# STM32F105 register map
File version: 1.3
CPU: CM3 r1p1, little endian, no MPU, no FPU, 4 interrupt priority bits
Registers are 32-bit, read-write, reset 0x0 unless marked. A register's access mark holds for its fields unless they carry their own. Offsets are from the block's base; [hi:lo] are bit positions; {n}, {i} and the like mark numbered series; 'fields as' and 'values as' point back to an identical list.

## UART4 — Universal asynchronous receiver transmitter
Base 0x40004C00
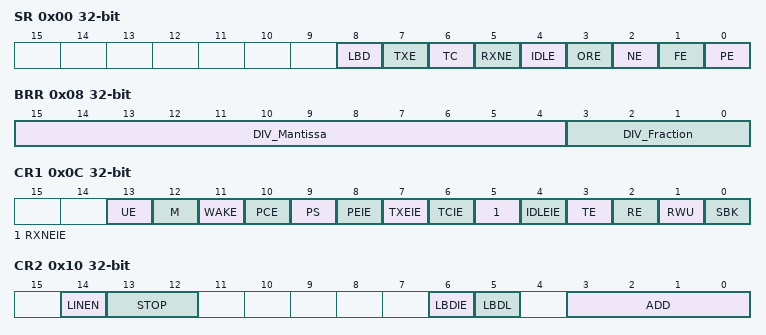
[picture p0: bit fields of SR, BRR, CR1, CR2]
0x00 SR access per field — UART4 SR
  [8] LBD rw — LIN break detection flag
  [7] TXE ro — Transmit data register empty
  [6] TC rw — Transmission complete
  [5] RXNE rw — Read data register not empty
  [4] IDLE ro — IDLE line detected
  [3] ORE ro — Overrun error
  [2] NE ro — Noise error flag
  [1] FE ro — Framing error
  [0] PE ro — Parity error
0x04 DR — UART4 DR
  [8:0] DR
0x08 BRR — UART4 BRR
  [15:4] DIV_Mantissa, [3:0] DIV_Fraction
0x0C CR1 — UART4 CR1
  [13] UE — USART enable
  [12] M — Word length
  [11] WAKE — Wakeup method
  [10] PCE — Parity control enable
  [9] PS — Parity selection
  [8] PEIE — PE interrupt enable
  [7] TXEIE — TXE interrupt enable
  [6] TCIE — Transmission complete interrupt enable
  [5] RXNEIE — RXNE interrupt enable
  [4] IDLEIE — IDLE interrupt enable
  [3] TE — Transmitter enable
  [2] RE — Receiver enable
  [1] RWU — Receiver wakeup
  [0] SBK — Send break
0x10 CR2 — UART4 CR2
  [14] LINEN — LIN mode enable
  [13:12] STOP — STOP bits
  [6] LBDIE — LIN break detection interrupt enable
  [5] LBDL — lin break detection length
  [3:0] ADD — Address of the USART node
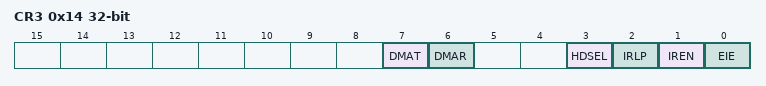
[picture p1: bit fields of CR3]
0x14 CR3 — UART4 CR3
  [7] DMAT — DMA enable transmitter
  [6] DMAR — DMA enable receiver
  [3] HDSEL — Half-duplex selection
  [2] IRLP — IrDA low-power
  [1] IREN — IrDA mode enable
  [0] EIE — Error interrupt enable

## UART5 — Universal asynchronous receiver transmitter
Base 0x40005000
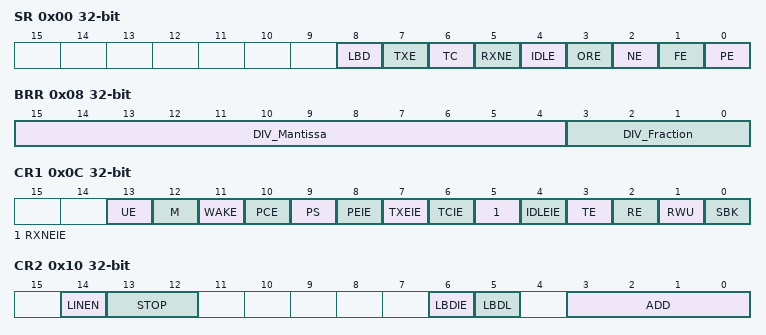
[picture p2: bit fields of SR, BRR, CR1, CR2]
0x00 SR access per field — UART5 SR
  [8] LBD rw, [7] TXE ro, [6] TC rw, [5] RXNE rw, [4] IDLE ro, [3] ORE ro, [2] NE ro, [1] FE ro, [0] PE ro
0x04 DR — UART5 DR
  [8:0] DR
0x08 BRR — UART5 BRR
  [15:4] DIV_Mantissa, [3:0] DIV_Fraction
0x0C CR1 — UART5 CR1
  [13] UE, [12] M, [11] WAKE, [10] PCE, [9] PS, [8] PEIE, [7] TXEIE, [6] TCIE, [5] RXNEIE, [4] IDLEIE, [3] TE, [2] RE, [1] RWU, [0] SBK
0x10 CR2 — UART5 CR2
  [14] LINEN, [13:12] STOP, [6] LBDIE, [5] LBDL, [3:0] ADD
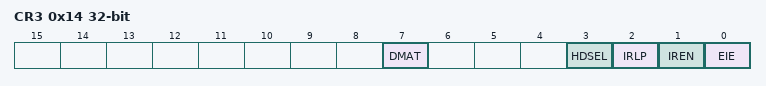
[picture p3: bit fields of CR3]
0x14 CR3 — UART5 CR3
  [7] DMAT — DMA enable transmitter
  [3] HDSEL — Half-duplex selection
  [2] IRLP — IrDA low-power
  [1] IREN — IrDA mode enable
  [0] EIE — Error interrupt enable

## USB_OTG_HOST — USB on the go full speed
Base 0x50000400
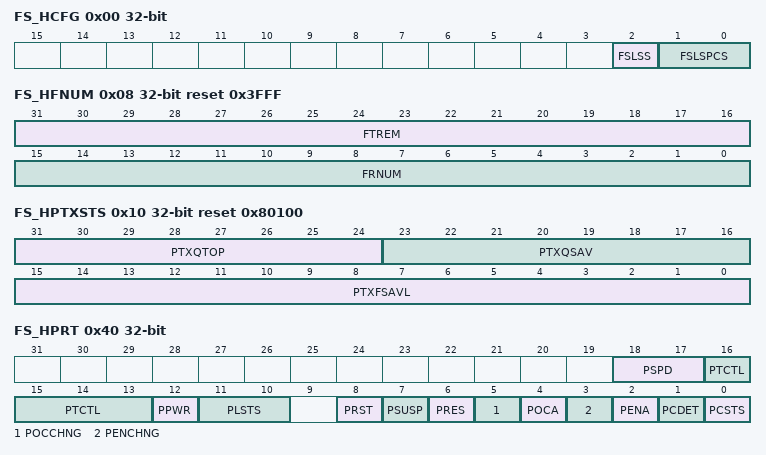
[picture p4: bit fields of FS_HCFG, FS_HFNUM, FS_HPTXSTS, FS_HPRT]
0x00 FS_HCFG access per field — OTG_FS host configuration register (OTG_FS_HCFG)
  [2] FSLSS ro — FS- and LS-only support
  [1:0] FSLSPCS rw — FS/LS PHY clock select
0x04 HFIR reset 0xEA60 — OTG_FS Host frame interval register
  [15:0] FRIVL — Frame interval
0x08 FS_HFNUM ro reset 0x3FFF — OTG_FS host frame number/frame time remaining register (OTG_FS_HFNUM)
  [31:16] FTREM — Frame time remaining
  [15:0] FRNUM — Frame number
0x10 FS_HPTXSTS access per field reset 0x80100 — OTG_FS_Host periodic transmit FIFO/queue status register (OTG_FS_HPTXSTS)
  [31:24] PTXQTOP ro — Top of the periodic transmit request queue
  [23:16] PTXQSAV ro — Periodic transmit request queue space available
  [15:0] PTXFSAVL rw — Periodic transmit data FIFO space available
0x14 HAINT ro — OTG_FS Host all channels interrupt register
  [15:0] HAINT — Channel interrupts
0x18 HAINTMSK — OTG_FS host all channels interrupt mask register
  [15:0] HAINTM — Channel interrupt mask
0x40 FS_HPRT access per field — OTG_FS host port control and status register (OTG_FS_HPRT)
  [18:17] PSPD ro — Port speed
  [16:13] PTCTL rw — Port test control
  [12] PPWR rw — Port power
  [11:10] PLSTS ro — Port line status
  [8] PRST rw — Port reset
  [7] PSUSP rw — Port suspend
  [6] PRES rw — Port resume
  [5] POCCHNG rw — Port overcurrent change
  [4] POCA ro — Port overcurrent active
  [3] PENCHNG rw — Port enable/disable change
  [2] PENA rw — Port enable
  [1] PCDET rw — Port connect detected
  [0] PCSTS ro — Port connect status
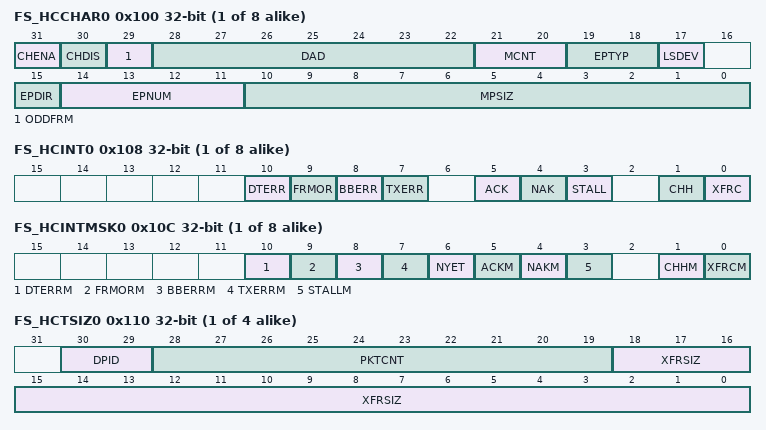
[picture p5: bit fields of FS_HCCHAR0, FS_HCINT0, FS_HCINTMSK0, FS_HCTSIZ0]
{0x100+0x20*i} FS_HCCHAR{i} (i=0..7) — OTG_FS host channel-{i} characteristics register (OTG_FS_HCCHAR{i})
  [31] CHENA — Channel enable
  [30] CHDIS — Channel disable
  [29] ODDFRM — Odd frame
  [28:22] DAD — Device address
  [21:20] MCNT — Multicount
  [19:18] EPTYP — Endpoint type
  [17] LSDEV — Low-speed device
  [15] EPDIR — Endpoint direction
  [14:11] EPNUM — Endpoint number
  [10:0] MPSIZ — Maximum packet size
{0x108+0x20*i} FS_HCINT{i} (i=0..7) — OTG_FS host channel-{i} interrupt register (OTG_FS_HCINT{i})
  [10] DTERR — Data toggle error
  [9] FRMOR — Frame overrun
  [8] BBERR — Babble error
  [7] TXERR — Transaction error
  [5] ACK — ACK response received/transmitted interrupt
  [4] NAK — NAK response received interrupt
  [3] STALL — STALL response received interrupt
  [1] CHH — Channel halted
  [0] XFRC — Transfer completed
{0x10C+0x20*i} FS_HCINTMSK{i} (i=0..7) — OTG_FS host channel-{i} mask register (OTG_FS_HCINTMSK{i})
  [10] DTERRM — Data toggle error mask
  [9] FRMORM — Frame overrun mask
  [8] BBERRM — Babble error mask
  [7] TXERRM — Transaction error mask
  [6] NYET — response received interrupt mask
  [5] ACKM — ACK response received/transmitted interrupt mask
  [4] NAKM — NAK response received interrupt mask
  [3] STALLM — STALL response received interrupt mask
  [1] CHHM — Channel halted mask
  [0] XFRCM — Transfer completed mask
{0x110+0x20*i} FS_HCTSIZ{i} (i=0..3) — OTG_FS host channel-{i} transfer size register
  [30:29] DPID — Data PID
  [28:19] PKTCNT — Packet count
  [18:0] XFRSIZ — Transfer size
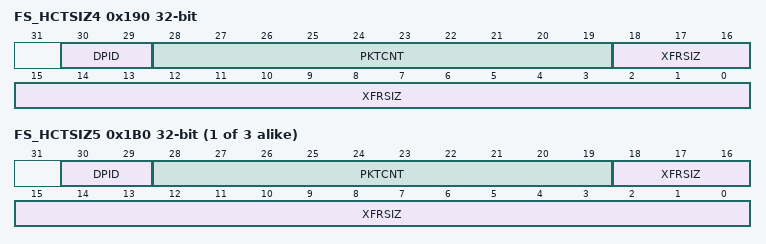
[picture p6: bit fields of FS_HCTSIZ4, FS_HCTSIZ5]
0x190 FS_HCTSIZ4 — OTG_FS host channel-x transfer size register
  fields as FS_HCTSIZ0
{0x110+0x20*i} FS_HCTSIZ{i} (i=5..7) — OTG_FS host channel-{i} transfer size register
  fields as FS_HCTSIZ0

## USB_OTG_PWRCLK — USB on the go full speed
Base 0x50000E00
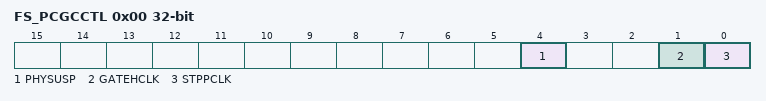
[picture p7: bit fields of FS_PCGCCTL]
0x00 FS_PCGCCTL — OTG_FS power and clock gating control register (OTG_FS_PCGCCTL)
  [4] PHYSUSP — PHY Suspended
  [1] GATEHCLK
  [0] STPPCLK — Stop PHY clock

## WWDG — Window watchdog
Base 0x40002C00
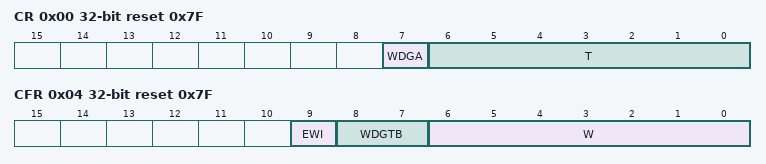
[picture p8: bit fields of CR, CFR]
0x00 CR reset 0x7F — Control register (WWDG_CR)
  [7] WDGA — Activation bit
  [6:0] T — 7-bit counter (MSB to LSB)
0x04 CFR reset 0x7F — Configuration register (WWDG_CFR)
  [9] EWI — Early Wakeup Interrupt
  [8:7] WDGTB — Timer Base
  [6:0] W — 7-bit window value
0x08 SR — Status register (WWDG_SR)
  [0] EWI — Early Wakeup Interrupt
